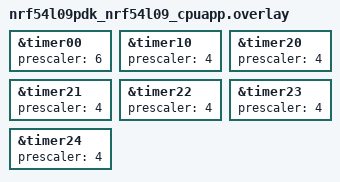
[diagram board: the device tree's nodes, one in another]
&timer00 {
	prescaler = <6>;
	status = "okay";
};

&timer10 {
	prescaler = <4>;
	status = "okay";
};

&timer20 {
	prescaler = <4>;
	status = "okay";
};

&timer21 {
	prescaler = <4>;
	status = "okay";
};

&timer22 {
	prescaler = <4>;
	status = "okay";
};

&timer23 {
	prescaler = <4>;
	status = "okay";
};

&timer24 {
	prescaler = <4>;
	status = "okay";
};
